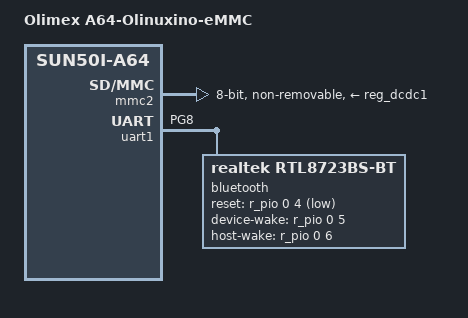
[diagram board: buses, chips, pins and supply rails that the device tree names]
// SPDX-License-Identifier: (GPL-2.0+ OR MIT)
// Copyright (C) 2018 Martin Ayotte <martinayotte@gmail.com>
// Copyright (C) 2019 Sunil Mohan Adapa <sunil@medhas.org>

#include "sun50i-a64-olinuxino.dts"

/ {
	model = "Olimex A64-Olinuxino-eMMC";
	compatible = "olimex,a64-olinuxino-emmc", "allwinner,sun50i-a64";
};

&mmc2 {
	pinctrl-names = "default";
	pinctrl-0 = <&mmc2_pins>;
	vmmc-supply = <&reg_dcdc1>;
	vqmmc-supply = <&reg_eldo1>;
	bus-width = <8>;
	non-removable;
	cap-mmc-hw-reset;
	status = "okay";
};

&pio {
	vcc-pc-supply = <&reg_eldo1>;
	uart1_cts_pins: uart1_cts_pins {
		pins = "PG8";
		function = "uart1";
	};
};

&uart1 {
        pinctrl-names = "default";
        pinctrl-0 = <&uart1_pins>, <&uart1_cts_pins>;
        status = "okay";
        bluetooth {
                compatible = "realtek,rtl8723bs-bt";
                reset-gpios = <&r_pio 0 4 GPIO_ACTIVE_LOW>; /* PL4 */
                device-wake-gpios = <&r_pio 0 5 GPIO_ACTIVE_HIGH>; /* PL5 */
                host-wake-gpios = <&r_pio 0 6 GPIO_ACTIVE_HIGH>; /* PL6 */
                firmware-postfix = "olinuxino";
        };
};
